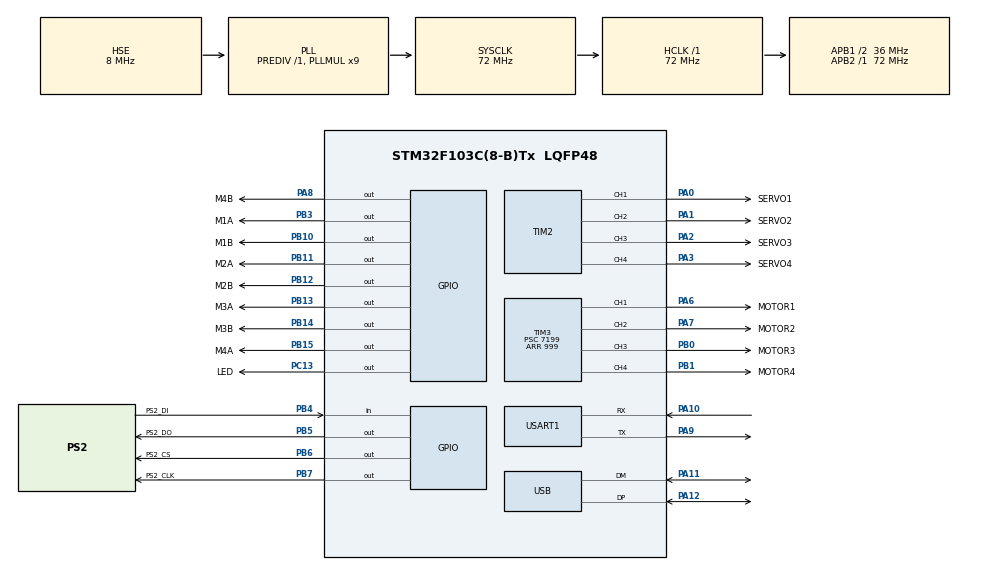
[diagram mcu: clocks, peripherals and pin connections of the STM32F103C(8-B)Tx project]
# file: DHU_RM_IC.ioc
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Mcu.Family=STM32F1
Mcu.Name=STM32F103C(8-B)Tx
Mcu.Package=LQFP48
NVIC.PriorityGroup=NVIC_PRIORITYGROUP_4
NVIC.USB_LP_CAN1_RX0_IRQn=true\:0\:0\:false\:false\:true\:false\:true
PA0-WKUP.GPIO_Label=SERVO1
PA0-WKUP.Signal=S_TIM2_CH1_ETR
PA1.GPIO_Label=SERVO2
PA1.Signal=S_TIM2_CH2
PA10.Mode=Asynchronous
PA10.Signal=USART1_RX
PA11.Mode=Device
PA11.Signal=USB_DM
PA12.Mode=Device
PA12.Signal=USB_DP
PA13.Mode=Serial_Wire
PA13.Signal=SYS_JTMS-SWDIO
PA14.Mode=Serial_Wire
PA14.Signal=SYS_JTCK-SWCLK
PA2.GPIO_Label=SERVO3
PA2.Signal=S_TIM2_CH3
PA3.GPIO_Label=SERVO4
PA3.Signal=S_TIM2_CH4
PA6.GPIO_Label=MOTOR1
PA6.Signal=S_TIM3_CH1
PA7.GPIO_Label=MOTOR2
PA7.Signal=S_TIM3_CH2
PA8.GPIO_Label=M4B
PA8.Signal=GPIO_Output
PA9.Mode=Asynchronous
PA9.Signal=USART1_TX
PB0.GPIO_Label=MOTOR3
PB0.Signal=S_TIM3_CH3
PB1.GPIO_Label=MOTOR4
PB1.Signal=S_TIM3_CH4
PB10.GPIO_Label=M1B
PB10.Signal=GPIO_Output
PB11.GPIO_Label=M2A
PB11.Signal=GPIO_Output
PB12.GPIO_Label=M2B
PB12.Signal=GPIO_Output
PB13.GPIO_Label=M3A
PB13.Signal=GPIO_Output
PB14.GPIO_Label=M3B
PB14.Signal=GPIO_Output
PB15.GPIO_Label=M4A
PB15.Signal=GPIO_Output
PB3.GPIO_Label=M1A
PB3.Signal=GPIO_Output
PB4.GPIO_Label=PS2_DI
PB4.Signal=GPIO_Input
PB5.GPIO_Label=PS2_DO
PB5.Signal=GPIO_Output
PB6.GPIO_Label=PS2_CS
PB6.Signal=GPIO_Output
PB7.GPIO_Label=PS2_CLK
PB7.Signal=GPIO_Output
PC13-TAMPER-RTC.GPIO_Label=LED
PC13-TAMPER-RTC.Signal=GPIO_Output
PC14-OSC32_IN.Mode=LSE-External-Oscillator
PC14-OSC32_IN.Signal=RCC_OSC32_IN
PC15-OSC32_OUT.Mode=LSE-External-Oscillator
PC15-OSC32_OUT.Signal=RCC_OSC32_OUT
PD0-OSC_IN.Mode=HSE-External-Oscillator
PD0-OSC_IN.Signal=RCC_OSC_IN
PD1-OSC_OUT.Mode=HSE-External-Oscillator
PD1-OSC_OUT.Signal=RCC_OSC_OUT
ProjectManager.HeapSize=0x200
ProjectManager.StackSize=0x400
ProjectManager.TargetToolchain=MDK-ARM V5.27
RCC.AHBFreq_Value=72000000
RCC.APB1CLKDivider=RCC_HCLK_DIV2
RCC.APB1Freq_Value=36000000
RCC.APB1TimFreq_Value=72000000
RCC.APB2Freq_Value=72000000
RCC.APB2TimFreq_Value=72000000
RCC.HCLKFreq_Value=72000000
RCC.PLLMUL=RCC_PLL_MUL9
RCC.PLLSourceVirtual=RCC_PLLSOURCE_HSE
RCC.SYSCLKFreq_VALUE=72000000
RCC.SYSCLKSource=RCC_SYSCLKSOURCE_PLLCLK
RCC.USBFreq_Value=48000000
RCC.USBPrescaler=RCC_USBCLKSOURCE_PLL_DIV1_5
SH.S_TIM2_CH1_ETR.0=TIM2_CH1,PWM Generation1 CH1
SH.S_TIM2_CH2.0=TIM2_CH2,PWM Generation2 CH2
SH.S_TIM2_CH3.0=TIM2_CH3,PWM Generation3 CH3
SH.S_TIM2_CH4.0=TIM2_CH4,PWM Generation4 CH4
SH.S_TIM3_CH1.0=TIM3_CH1,PWM Generation1 CH1
SH.S_TIM3_CH2.0=TIM3_CH2,PWM Generation2 CH2
SH.S_TIM3_CH3.0=TIM3_CH3,PWM Generation3 CH3
SH.S_TIM3_CH4.0=TIM3_CH4,PWM Generation4 CH4
TIM2.Channel-PWM\ Generation1\ CH1=TIM_CHANNEL_1
TIM2.Channel-PWM\ Generation2\ CH2=TIM_CHANNEL_2
TIM2.Channel-PWM\ Generation3\ CH3=TIM_CHANNEL_3
TIM2.Channel-PWM\ Generation4\ CH4=TIM_CHANNEL_4
TIM3.Channel-PWM\ Generation1\ CH1=TIM_CHANNEL_1
TIM3.Channel-PWM\ Generation2\ CH2=TIM_CHANNEL_2
TIM3.Channel-PWM\ Generation3\ CH3=TIM_CHANNEL_3
TIM3.Channel-PWM\ Generation4\ CH4=TIM_CHANNEL_4
TIM3.Period=999
TIM3.Prescaler=7199
USART1.VirtualMode=VM_ASYNC
USB_DEVICE.CLASS_NAME_FS=CDC
USB_DEVICE.VirtualMode=Cdc
USB_DEVICE.VirtualModeFS=Cdc_FS
VP_USB_DEVICE_VS_USB_DEVICE_CDC_FS.Mode=CDC_FS
board=custom

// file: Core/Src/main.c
/* USER CODE BEGIN Header */
/**
  ******************************************************************************
  * @file           : main.c
  * @brief          : Main program body
  ******************************************************************************
  * @attention
  *
  * <h2><center>&copy; Copyright (c) 2020 STMicroelectronics.
  * All rights reserved.</center></h2>
  *
  * This software component is licensed by ST under Ultimate Liberty license
  * SLA0044, the "License"; You may not use this file except in compliance with
  * the License. You may obtain a copy of the License at:
  *                             www.st.com/SLA0044
  *
  ******************************************************************************
  */
/* USER CODE END Header */
#include "main.h"
#include "tim.h"
#include "usart.h"
#include "usb_device.h"
#include "gpio.h"

/* USER CODE BEGIN Includes */

#include "bsp_ps2.h"
#include "bsp_motor.h"
#include "bsp_usart.h"

/* USER CODE END Includes */

void SystemClock_Config(void);

int main(void)
{

    /* MCU Configuration--------------------------------------------------------*/

    /* Reset of all peripherals, Initializes the Flash interface and the Systick. */
    HAL_Init();

    /* Configure the system clock */
    SystemClock_Config();

    /* Initialize all configured peripherals */
    MX_GPIO_Init();
    MX_TIM2_Init();
    MX_TIM3_Init();
    MX_USB_DEVICE_Init();
    MX_USART1_UART_Init();
    /* USER CODE BEGIN 2 */

    // 初始化PS2
    PS2_SetInit();

    // 开启TIM3 PWM输出 默认0
    HAL_TIM_PWM_Start(&M1TIM,TIM_CHANNEL_1);
    HAL_TIM_PWM_Start(&M2TIM,TIM_CHANNEL_2);
    HAL_TIM_PWM_Start(&M3TIM,TIM_CHANNEL_3);
    HAL_TIM_PWM_Start(&M4TIM,TIM_CHANNEL_4);

    /* USER CODE END 2 */

    /* Infinite loop */
    while (1)
    {
        chassis_remote_control();
    }
}

void SystemClock_Config(void)
{
    RCC_OscInitTypeDef RCC_OscInitStruct = {0};
    RCC_ClkInitTypeDef RCC_ClkInitStruct = {0};
    RCC_PeriphCLKInitTypeDef PeriphClkInit = {0};

    /** Initializes the RCC Oscillators according to the specified parameters
    * in the RCC_OscInitTypeDef structure.
    */
    RCC_OscInitStruct.OscillatorType = RCC_OSCILLATORTYPE_HSE;
    RCC_OscInitStruct.HSEState = RCC_HSE_ON;
    RCC_OscInitStruct.HSEPredivValue = RCC_HSE_PREDIV_DIV1;
    RCC_OscInitStruct.HSIState = RCC_HSI_ON;
    RCC_OscInitStruct.PLL.PLLState = RCC_PLL_ON;
    RCC_OscInitStruct.PLL.PLLSource = RCC_PLLSOURCE_HSE;
    RCC_OscInitStruct.PLL.PLLMUL = RCC_PLL_MUL9;
    if (HAL_RCC_OscConfig(&RCC_OscInitStruct) != HAL_OK)
    {
        Error_Handler();
    }
    /** Initializes the CPU, AHB and APB buses clocks
    */
    RCC_ClkInitStruct.ClockType = RCC_CLOCKTYPE_HCLK|RCC_CLOCKTYPE_SYSCLK
                                  |RCC_CLOCKTYPE_PCLK1|RCC_CLOCKTYPE_PCLK2;
    RCC_ClkInitStruct.SYSCLKSource = RCC_SYSCLKSOURCE_PLLCLK;
    RCC_ClkInitStruct.AHBCLKDivider = RCC_SYSCLK_DIV1;
    RCC_ClkInitStruct.APB1CLKDivider = RCC_HCLK_DIV2;
    RCC_ClkInitStruct.APB2CLKDivider = RCC_HCLK_DIV1;

    if (HAL_RCC_ClockConfig(&RCC_ClkInitStruct, FLASH_LATENCY_2) != HAL_OK)
    {
        Error_Handler();
    }
    PeriphClkInit.PeriphClockSelection = RCC_PERIPHCLK_USB;
    PeriphClkInit.UsbClockSelection = RCC_USBCLKSOURCE_PLL_DIV1_5;
    if (HAL_RCCEx_PeriphCLKConfig(&PeriphClkInit) != HAL_OK)
    {
        Error_Handler();
    }
}

void Error_Handler(void)
{
}

/************************ (C) COPYRIGHT STMicroelectronics *****END OF FILE****/
